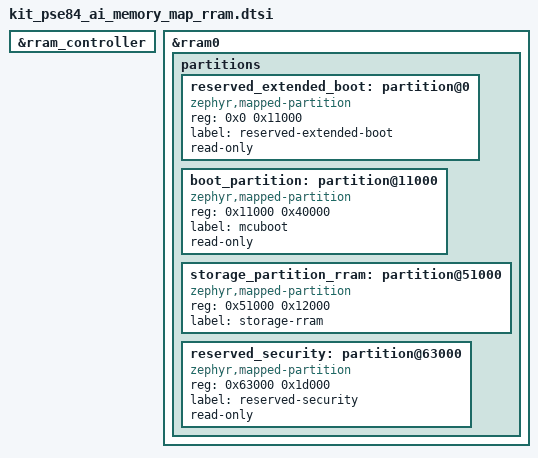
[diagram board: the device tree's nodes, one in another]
/*
 * SPDX-FileCopyrightText: Copyright (c) 2026 Infineon Technologies AG,
 * SPDX-FileCopyrightText: or an affiliate of Infineon Technologies AG. All rights reserved.
 *
 * SPDX-License-Identifier: Apache-2.0
 */

/* RRAM memory (512 KB) assignment
 *   0x00000 - 0x10FFF : reserved-extended-boot (68 KB)
 *   0x11000 - 0x50FFF : boot_partition (256 KB) - MCUBoot bootloader
 *   0x51000 - 0x62FFF : storage_rram (72 KB)
 *   0x63000 - 0x7FFFF : reserved-security (116 KB)
 */
&rram_controller {
	status = "okay";
};

&rram0 {
	status = "okay";

	partitions {
		ranges;
		#address-cells = <1>;
		#size-cells = <1>;

		reserved_extended_boot: partition@0 {
			compatible = "zephyr,mapped-partition";
			reg = <0x0 0x11000>;
			label = "reserved-extended-boot";
			read-only;
		};

		boot_partition: partition@11000 {
			compatible = "zephyr,mapped-partition";
			reg = <0x11000 0x40000>;
			label = "mcuboot";
			read-only;
		};

		storage_partition_rram: partition@51000 {
			compatible = "zephyr,mapped-partition";
			reg = <0x51000 0x12000>;
			label = "storage-rram";
		};

		reserved_security: partition@63000 {
			compatible = "zephyr,mapped-partition";
			reg = <0x63000 0x1d000>;
			label = "reserved-security";
			read-only;
		};
	};
};
